# PIC32MM0064GPM036 device description
Architecture: MIPS; Family: PIC32MM1387; Series: PIC32MM
Registers are 32-bit, read-write, no defined reset value unless marked. A register's access mark holds for its fields unless they carry their own. Offsets are from the block's base; [hi:lo] are bit positions; {n}, {i} and the like mark numbered series; 'fields as' and 'values as' point back to an identical list.

## CDAC
Instances: CDAC 0x1f802380 in periph0
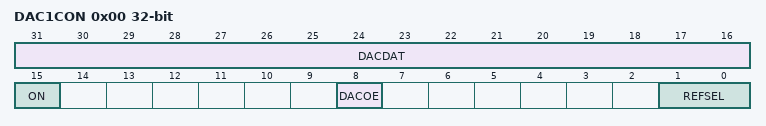
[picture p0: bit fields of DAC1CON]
0x00 DAC1CON — CDAC Control Register
  [31:16] DACDAT — Data Input Register Bits for the CDAC
  [15] ON — CDAC Enable
    0=The CDAC is Disabled; 1=The CDAC is Enabled
  [8] DACOE — CDAC Output Enable
    0=Output is Disabled; drive to pin is floating; 1=Output is Enabled; CDAC voltage is connected to the pin
  [1:0] REFSEL — Reference Source Select
    0=No reference is selected (output is AVSS); 1=Reference voltage is the CVREF+ input pin voltage; 2=No reference is selected (output is AVSS); 3=Reference voltage is AVDD

## CFG
Instances: CFG 0x1f802910 in periph0
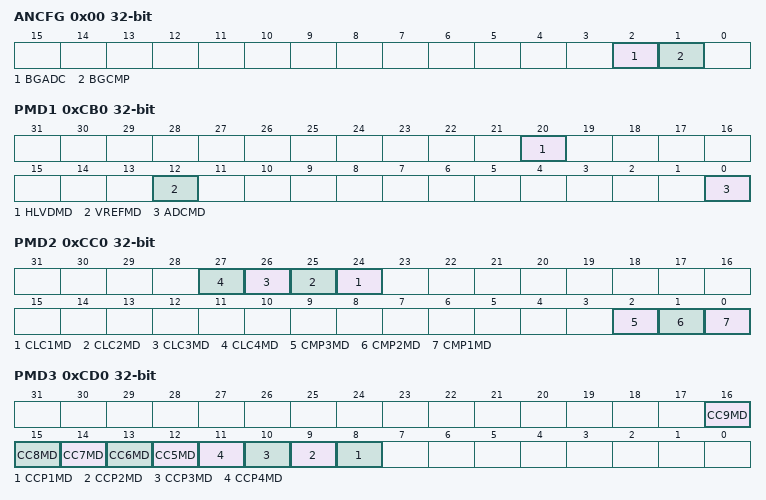
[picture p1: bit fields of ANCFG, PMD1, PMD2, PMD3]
0x00 ANCFG
  [2] BGADC, [1] BGCMP
0xCA0 PMDCON
  [11] PMDLOCK
0xCB0 PMD1
  [20] HLVDMD, [12] VREFMD, [0] ADCMD
0xCC0 PMD2
  [n+23] CLC{n}MD (n=1..4), [2] CMP3MD, [1] CMP2MD, [0] CMP1MD
0xCD0 PMD3
  [n+7] CC{n}MD (n=5..9), [n+7] CCP{n}MD (n=1..4)
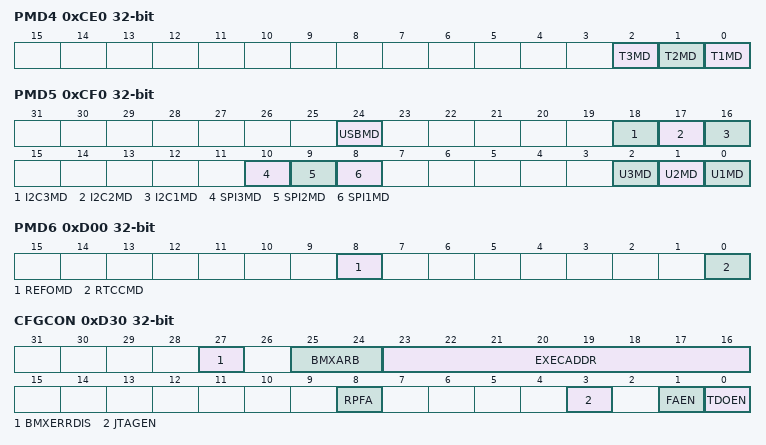
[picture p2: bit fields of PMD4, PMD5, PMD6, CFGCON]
0xCE0 PMD4
  [2] T3MD, [1] T2MD, [0] T1MD
0xCF0 PMD5
  [24] USBMD, [18] I2C3MD, [17] I2C2MD, [16] I2C1MD, [10] SPI3MD, [9] SPI2MD, [8] SPI1MD, [2] U3MD, [1] U2MD, [0] U1MD
0xD00 PMD6
  [8] REFOMD, [0] RTCCMD
0xD10 PMD7
  [4] DMAMD
0xD30 CFGCON
  [27] BMXERRDIS
  [25:24] BMXARB
  [23:16] EXECADDR
  [8] RPFA
  [3] JTAGEN — JTAG Port Enable bit
    1=Enable the JTAG port; 0=Disable the JTAG port
  [1] FAEN
  [0] TDOEN — TDO Enable for 2-Wire JTAG
    1=2-wire JTAG protocol uses TDO; 0=2-wire JTAG protocol does not use TDO
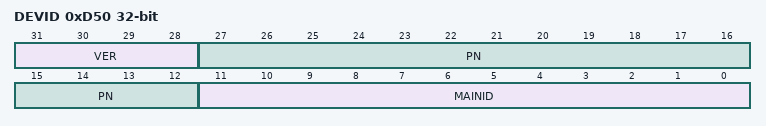
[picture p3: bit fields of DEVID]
0xD50 DEVID ro
  [31:28] VER, [27:12] PN, [11:0] MAINID
0xD60 SYSKEY

## CMP
Instances: CMP 0x1f802300 in periph0
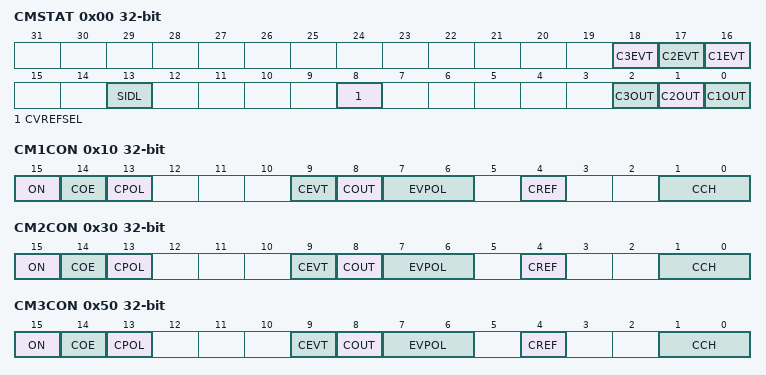
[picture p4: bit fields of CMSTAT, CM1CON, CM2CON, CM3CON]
0x00 CMSTAT
  [18] C3EVT
  [17] C2EVT
  [16] C1EVT
  [13] SIDL — Stop in Idle Control bit
    1=All Comparator modules are disabled in Idle mode; 0=All Comparator modules continue to operate in the Idle mode
  [8] CVREFSEL — Comparator Reference Voltage Select (CVREFSEL)
    1=External voltage reference from the CVREF+ pin is selected; 0=Internal band gap voltage reference is selected
  [2] C3OUT — Comparator 3 Output bit
    1=Output of Comparator 3 is a 1; 0=Output of Comparator 3 is a 0
  [1] C2OUT — Comparator 2 Output bit
    1=Output of Comparator 2 is a 1; 0=Output of Comparator 2 is a 0
  [0] C1OUT — Comparator 1 Output bit
    1=Output of Comparator 1 is a 1; 0=Output of Comparator 1 is a 0
0x10 CM1CON
  [15] ON — Comparator ON bit
    1=Module is enabled. Setting this bit does not affect the other bits in this register; 0=Module is disabled and does not consume current. Clearing this bit does not affect the other bits in this register
  [14] COE — Comparator Output Enable bit
    1=Comparator output is driven on the output CxOUT pin; 0=Comparator output is not driven on the output CxOUT pin
  [13] CPOL — Comparator Output Inversion bit
    1=Output is inverted; 0=Output is not inverted
  [9] CEVT
  [8] COUT — Comparator Output bit
    1=VIN+ is greater than VIN- (if CPOL = 0)/VIN+ is smaller than VIN- (if CPOL = 1); 0=VIN+ is greater than VIN- (if CPOL = 1)/VIN+ is smaller than VIN- (if CPOL = 0)
  [7:6] EVPOL — Interrupt Event Polarity Select bits
    3=Comparator event is generated on any change of the comparator output; 2=Comparator event is generated on a high-to-low transition (if CPOL = 0) or low-to-high transition (if CPOL = 1) of the comparator output; 1=Comparator event is generated on a high-to-low transition (if CPOL = 1) or low-to-high transition (if CPOL = 0) of the comparator output; 0=Comparator event generation is disabled
  [4] CREF — Comparator Positive Input Configuration
    1=Comparator Non-inverting input connects to the reference defined by the CVREFSEL bit; 0=Comparator non-inverting input is connected to the CxINA pin
  [1:0] CCH — Comparator Negative Input Configuration
    3=Comparator inverting input is connected to the band gap reference voltage; 2=Comparator inverting input is connected to the CxIND pin; 1=Comparator inverting input is connected to the CxINC pin; 0=Comparator inverting input is connected to the CxINB pin
0x30 CM2CON
  fields as CM1CON
0x50 CM3CON
  fields as CM1CON

## Notices in the file
Copyright (c) 2019 Microchip Technology Inc.
SPDX-License-Identifier: Apache-2.0
Licensed under the Apache License, Version 2.0 (the "License");
you may not use this file except in compliance with the License.
You may obtain a copy of the License at
http://www.apache.org/licenses/LICENSE-2.0
Unless required by applicable law or agreed to in writing, software
distributed under the License is distributed on an "AS IS" BASIS,
WITHOUT WARRANTIES OR CONDITIONS OF ANY KIND, either express or implied.
See the License for the specific language governing permissions and
limitations under the License.
